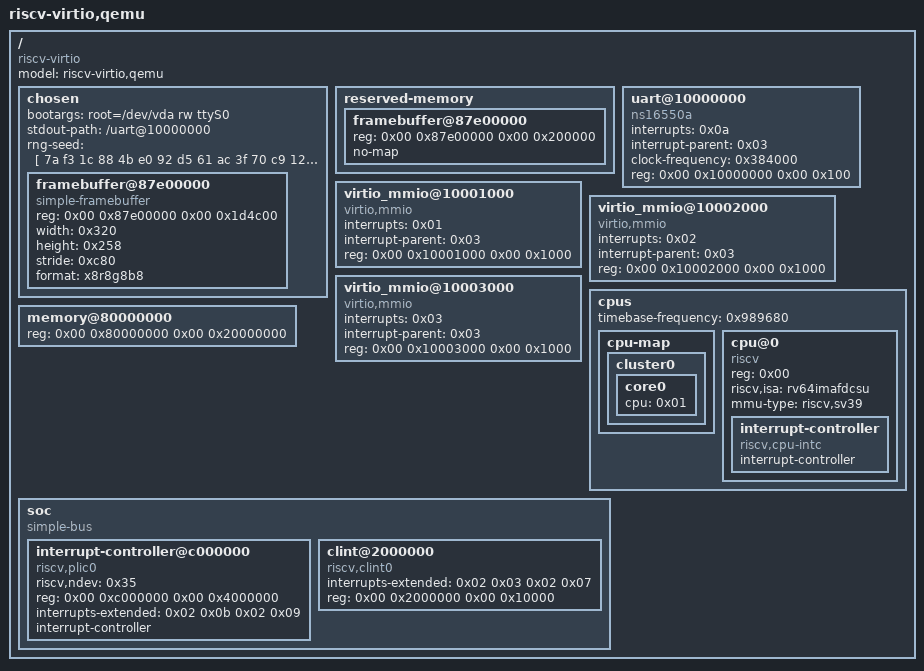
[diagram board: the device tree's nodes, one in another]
/dts-v1/;

// risc-box patch: source for the default device tree (upstream ships only the
// compiled dtb.dtb). Identical to upstream's tree plus two additions: the
// virtio-net device at 0x10002000 on PLIC IRQ 2, and a simple-framebuffer —
// 800x600 XRGB8888 in the top 2 MiB of DRAM (reserved-memory keeps the
// kernel's allocator off it; the host scans it out to the browser console).
// A kernel with CONFIG_FB_SIMPLE + CONFIG_FRAMEBUFFER_CONSOLE sees /dev/fb0;
// a kernel without them ignores the node — the sample serial image is
// untouched. Rebuild with:
//   dtc -I dts -O dtb -o dtb.dtb dtb.dts
// The compiled blob must stay under DTB_SIZE (0xfe0) in mmu.rs; it is mapped
// at physical 0x1020 and handed to the kernel via a1.

/ {
	#address-cells = <0x02>;
	#size-cells = <0x02>;
	compatible = "riscv-virtio";
	model = "riscv-virtio,qemu";

	chosen {
		#address-cells = <0x02>;
		#size-cells = <0x02>;
		ranges;
		bootargs = "root=/dev/vda rw ttyS0";
		stdout-path = "/uart@10000000";

		// risc-box patch: seed the kernel CRNG at boot. The emulated machine has
		// no hardware RNG and few interrupts, so crng init otherwise takes ~160 s
		// — and userspace that needs entropy before then misbehaves (Xorg's
		// keyboard-init fork of xkbcomp fails while the pool is uninitialised).
		// The kernel credits this as boot entropy (add_bootloader_randomness) and
		// wipes it from the FDT after reading. A fixed seed is fine for a throwaway
		// demo box; a real deployment would inject a fresh one.
		rng-seed = [ 7a f3 1c 88 4b e0 92 d5 61 ac 3f 70 c9 12 5e bb
		             04 d8 2a 97 fe 63 15 4c a1 8b 39 f0 6d 27 b4 55
		             e2 91 0c 7f 38 ca 46 19 d3 84 5b a8 2f 6e c1 90
		             13 77 bd 40 e9 52 8c 21 fa 65 3d 9e 08 b7 4a d6 ];

		// risc-box patch: the guest's display. 800*600*4 = 0x1d4c00 bytes at
		// the top of the 128 MiB DRAM (0x87e00000..0x88000000 reserved below).
		framebuffer@87e00000 {
			compatible = "simple-framebuffer";
			reg = <0x00 0x87e00000 0x00 0x1d4c00>;
			width = <0x320>;
			height = <0x258>;
			stride = <0xc80>;
			format = "x8r8g8b8";
			status = "okay";
		};
	};

	reserved-memory {
		#address-cells = <0x02>;
		#size-cells = <0x02>;
		ranges;

		// risc-box patch: keep the allocator off the framebuffer pages
		framebuffer@87e00000 {
			reg = <0x00 0x87e00000 0x00 0x200000>;
			no-map;
		};
	};

	uart@10000000 {
		interrupts = <0x0a>;
		interrupt-parent = <0x03>;
		clock-frequency = <0x384000>;
		reg = <0x00 0x10000000 0x00 0x100>;
		compatible = "ns16550a";
	};

	virtio_mmio@10001000 {
		interrupts = <0x01>;
		interrupt-parent = <0x03>;
		reg = <0x00 0x10001000 0x00 0x1000>;
		compatible = "virtio,mmio";
	};

	virtio_mmio@10002000 {
		interrupts = <0x02>;
		interrupt-parent = <0x03>;
		reg = <0x00 0x10002000 0x00 0x1000>;
		compatible = "virtio,mmio";
	};

	// risc-box patch: virtio-input (device id 18) — a virtual HID (absolute
	// pointer + buttons + keyboard) the host injects events into, so a
	// graphical session (and a remote client driving it) has real input.
	virtio_mmio@10003000 {
		interrupts = <0x03>;
		interrupt-parent = <0x03>;
		reg = <0x00 0x10003000 0x00 0x1000>;
		compatible = "virtio,mmio";
	};

	cpus {
		#address-cells = <0x01>;
		#size-cells = <0x00>;
		timebase-frequency = <0x989680>;

		cpu-map {

			cluster0 {

				core0 {
					cpu = <0x01>;
				};
			};
		};

		cpu@0 {
			phandle = <0x01>;
			device_type = "cpu";
			reg = <0x00>;
			status = "okay";
			compatible = "riscv";
			riscv,isa = "rv64imafdcsu";
			mmu-type = "riscv,sv39";

			interrupt-controller {
				#interrupt-cells = <0x01>;
				interrupt-controller;
				compatible = "riscv,cpu-intc";
				phandle = <0x02>;
			};
		};
	};

	memory@80000000 {
		device_type = "memory";
		// risc-box patch: 512 MiB (was 128) — a desktop guest needs the RAM for
		// Xorg + clients, and X's fork of xkbcomp fails under 128 MiB. Must match
		// PROGRAM_MEMORY_CAPACITY in lib.rs. The framebuffer + its reserved-memory
		// hole at 0x87e00000 sit inside this range.
		reg = <0x00 0x80000000 0x00 0x20000000>;
	};

	soc {
		#address-cells = <0x02>;
		#size-cells = <0x02>;
		compatible = "simple-bus";
		ranges;

		interrupt-controller@c000000 {
			phandle = <0x03>;
			riscv,ndev = <0x35>;
			reg = <0x00 0xc000000 0x00 0x4000000>;
			interrupts-extended = <0x02 0x0b 0x02 0x09>;
			interrupt-controller;
			compatible = "riscv,plic0";
			#interrupt-cells = <0x01>;
			#address-cells = <0x00>;
		};

		clint@2000000 {
			interrupts-extended = <0x02 0x03 0x02 0x07>;
			reg = <0x00 0x2000000 0x00 0x10000>;
			compatible = "riscv,clint0";
		};
	};
};
